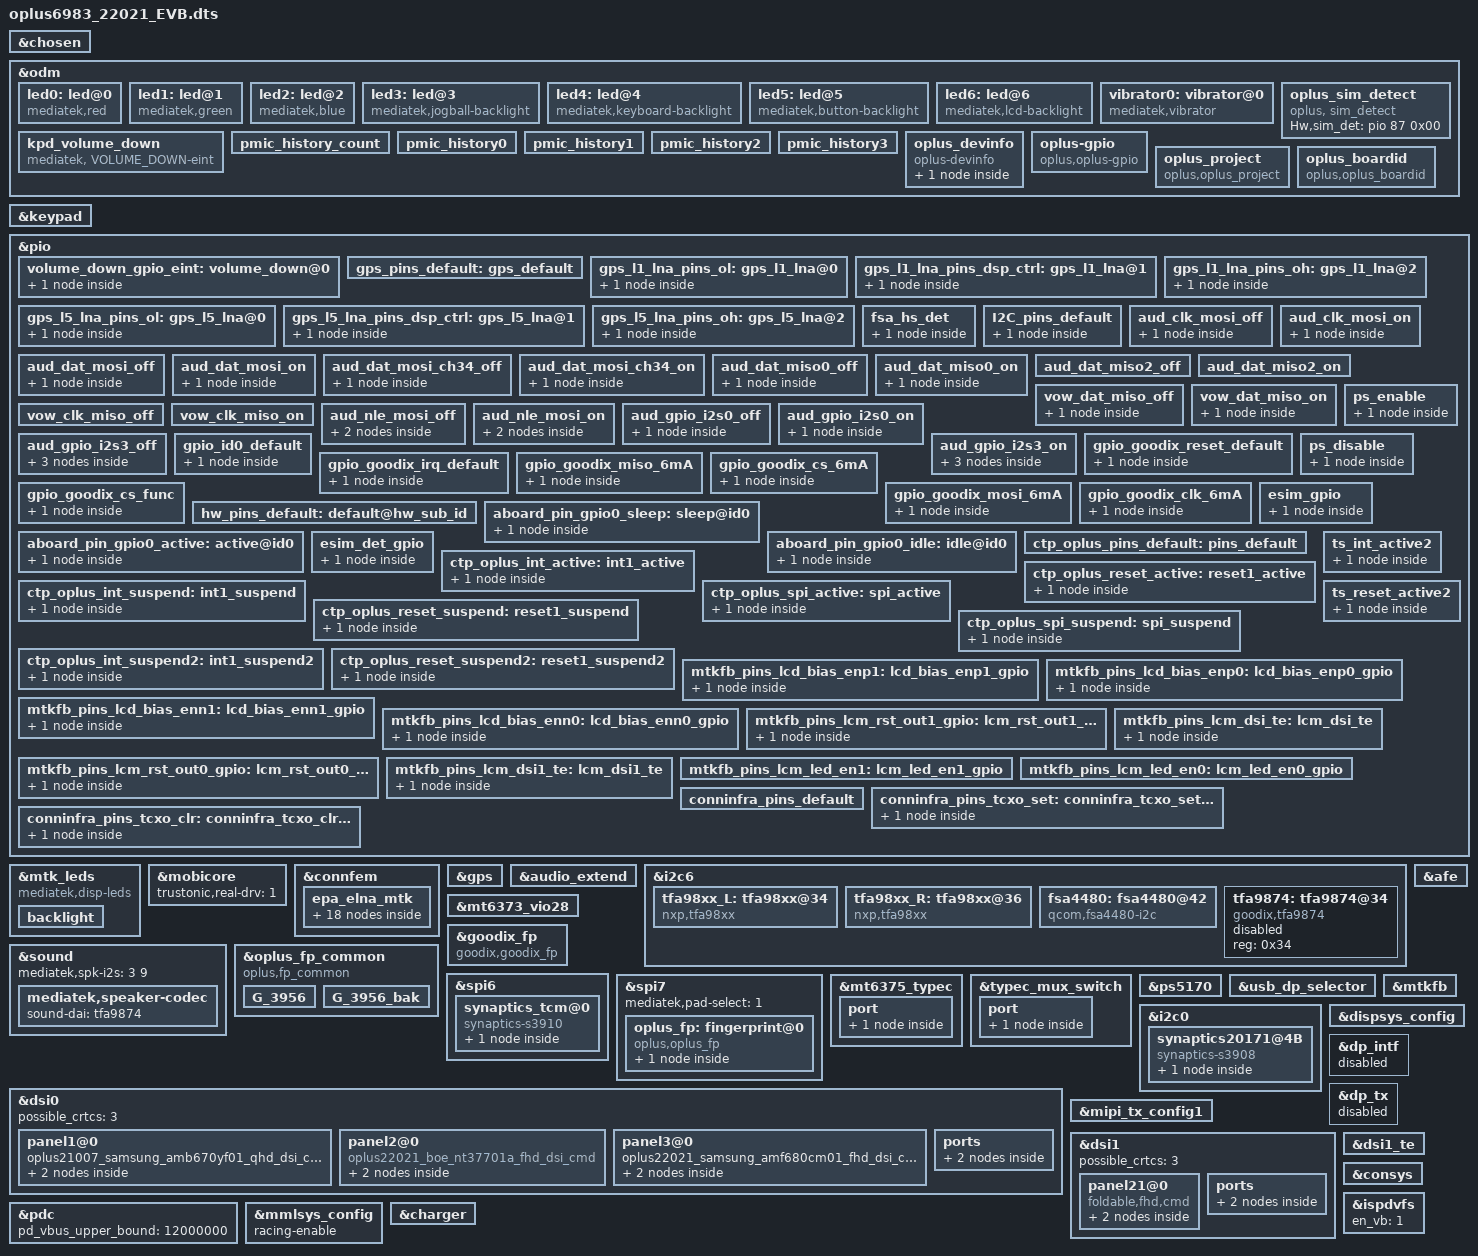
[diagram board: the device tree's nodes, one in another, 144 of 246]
// SPDX-License-Identifier: (GPL-2.0 OR MIT)
/*
 * Copyright (C) 2020 MediaTek Inc.
 */
/dts-v1/;
/plugin/;
#include <dt-bindings/interrupt-controller/arm-gic.h>
#include <dt-bindings/interrupt-controller/irq.h>
#include <dt-bindings/pinctrl/mt6983-pinfunc.h>
#include <dt-bindings/clock/mt6983-clk.h>
#include <dt-bindings/phy/phy.h>

//#ifdef OPLUS_FEATURE_CHG_BASIC
#include "mediatek/oplus_charge_22021.dtsi"
//#endif

//#ifdef OPLUS_FEATURE_SENSOR
#include "mediatek/oplus_sensor_22021.dtsi"
//#endif

//#ifdef OPLUS_FEATURE_NFC_BRINGUP
#include "mediatek/nfc/mt6983_dragonfly_22021_sn110.dtsi"
//#endif OPLUS_FEATURE_NFC_BRINGUP

#include "mediatek/fan53870-regulator_22021_EVB.dtsi"

#include "mediatek/cust_mt6983_dragonfly_22021_msdc.dtsi"

&chosen {
	bootargs_ext = "console=tty0 root=/dev/ram \
	androidboot.hardware=mt6983 \
	firmware_class.path=/vendor/firmware \
	allow_mismatched_32bit_el0";
};

&odm {
	led0:led@0 {
		compatible = "mediatek,red";
		led_mode = <0>;
		data = <1>;
		pwm_config = <0 0 0 0 0>;
	};
	led1:led@1 {
		compatible = "mediatek,green";
		led_mode = <0>;
		data = <1>;
		pwm_config = <0 0 0 0 0>;
	};
	led2:led@2 {
		compatible = "mediatek,blue";
		led_mode = <0>;
		data = <1>;
		pwm_config = <0 0 0 0 0>;
	};
	led3:led@3 {
		compatible = "mediatek,jogball-backlight";
		led_mode = <0>;
		data = <1>;
		pwm_config = <0 0 0 0 0>;
	};
	led4:led@4 {
		compatible = "mediatek,keyboard-backlight";
		led_mode = <0>;
		data = <1>;
		pwm_config = <0 0 0 0 0>;
	};
	led5:led@5 {
		compatible = "mediatek,button-backlight";
		led_mode = <0>;
		data = <1>;
		pwm_config = <0 0 0 0 0>;
	};
	led6:led@6 {
		compatible = "mediatek,lcd-backlight";
		led_mode = <4>;
		data = <1>;
		pwm_config = <0 1 0 0 0>;
	};
	vibrator0:vibrator@0 {
		compatible = "mediatek,vibrator";
		vib_timer = <25>;
		vib_limit = <9>;
		vib_vol= <9>;
	};
	kpd_volume_down:kpd_volume_down {
		compatible = "mediatek, VOLUME_DOWN-eint";
		interrupt-parent = <&pio>;
		interrupts = <12 IRQ_TYPE_EDGE_FALLING 12 0>;
		debounce = <32000>;
		status = "okay";
	};
};

&keypad {
	keypad,volume-down = <&pio 12 0x00>;
	pinctrl-names = "volume_down_as_int";
	pinctrl-0 = <&volume_down_gpio_eint>;
	status = "okay";
};

&pio {
	volume_down_gpio_eint:volume_down@0{
		pins_cmd_dat {
			pinmux = <PINMUX_GPIO12__FUNC_GPIO12>;
			slew-rate = <0>;  /*direction 0:in, 1:out*/
			input-enable;
		};
	};
};

&mtk_leds {
	compatible = "mediatek,disp-leds";
	backlight {
		label = "lcd-backlight";
		led_mode = <4>;
		max-brightness = <10239>;
		max-hw-brightness = <10239>;
		led-bits = <13>;
		};
};

/*Trustonic Mobicore real driver*/
&mobicore {
	trustonic,real-drv=<1>;
};

&connfem {
#if 0 /* Enable epa_elna node to support Wifi & BT ePA/eLNA FEM on customer load */
	epa_elna {
		parts = <&wlan7207h &wlan7205c>;

		wifi {
			flags-0 {
				open-loop;
			};
		};

		bt {
			flags-0 {
				/* choose one of: epa_elna / epa / elna / bypass */
				epa_elna;
			};
		};
	};
#endif

	epa_elna_mtk {
		parts = <&nofem &nofem>,		/* [0]iPA/iLNA */
			<&wlan7207h &wlan7205c_laa>,	/* [1]ePA/eLNA - Closed-Loop, LAA 4x4 */
			<&wlan7207h &wlan7205c>,	/* [2]ePA/eLNA - Open Loop */
			<&wlan7207h &wlan7205c>,	/* [3]ePA/eLNA - Closed-Loop */
			<&wlan7207h &wlan7205c_laa>,	/* [4]ePA/eLNA - Closed-Loop, LAA 4x4 */
			<&wlan7207h &wlan7205c>,	/* [5]ePA/eLNA - Closed-Loop + BT Bypass */
			<&wlan7207h &wlan7205c>,	/* [6]ePA/eLNA - Open Loop + BT Bypass */
			<&qm42195 &qm45197_laa>,	/* [7]Qorvo eFEM - Closed-Loop, LAA 4x4 */
			<&qm42195 &qm45197>,		/* [8]Qorvo eFEM - Open Loop */
			<&qm42195 &qm45197>;		/* [9]Qorvo eFEM - Closed-Loop */

		hwid {
			gpio = <&pio 203 0x0>;
		};

		wifi {
			flags-1 {
				laa;
			};
			flags-2 {
				open-loop;
			};
			flags-4 {
				laa;
			};
			flags-6 {
				open-loop;
			};
			flags-7 {
				laa;
			};
			flags-8 {
				open-loop;
			};
		};

		bt {
			flags-1 {
				/* choose one of: epa_elna / epa / elna / bypass */
				epa_elna;
			};
			flags-2 {
				epa_elna;
			};
			flags-3 {
				epa_elna;
			};
			flags-4 {
				epa_elna;
			};
			flags-5 {
				bypass;
			};
			flags-6 {
				bypass;
			};
			flags-7 {
				epa_elna;
			};
			flags-8 {
				epa_elna;
			};
			flags-9 {
				epa_elna;
			};
		};
	};
};

/* GPS GPIO standardization start */
&pio {
	gps_pins_default: gps_default {
	};

	gps_l1_lna_pins_ol: gps_l1_lna@0 {
		pins_cmd_dat {
			pinmux = <PINMUX_GPIO16__FUNC_GPIO16>;
			output-low;
		};
	};
	gps_l1_lna_pins_dsp_ctrl: gps_l1_lna@1 {
		pins_cmd_dat {
			pinmux = <PINMUX_GPIO16__FUNC_GPS_L1_ELNA_EN>;
		};
	};
	gps_l1_lna_pins_oh: gps_l1_lna@2 {
		pins_cmd_dat {
			pinmux = <PINMUX_GPIO16__FUNC_GPIO16>;
			output-high;
		};
	};

	gps_l5_lna_pins_ol: gps_l5_lna@0 {
		pins_cmd_dat {
			pinmux = <PINMUX_GPIO17__FUNC_GPIO17>;
			output-low;
		};
	};
	gps_l5_lna_pins_dsp_ctrl: gps_l5_lna@1 {
		pins_cmd_dat {
			pinmux = <PINMUX_GPIO17__FUNC_GPS_L5_ELNA_EN>;
		};
	};
	gps_l5_lna_pins_oh: gps_l5_lna@2 {
		pins_cmd_dat {
			pinmux = <PINMUX_GPIO17__FUNC_GPIO17>;
			output-high;
		};
	};
};

&gps {
	pinctrl-names = "default",
		"gps_l1_lna_disable",
		"gps_l1_lna_dsp_ctrl",
		"gps_l1_lna_enable",
		"gps_l5_lna_disable",
		"gps_l5_lna_dsp_ctrl",
		"gps_l5_lna_enable";
	pinctrl-0 = <&gps_pins_default>;
	pinctrl-1 = <&gps_l1_lna_pins_ol>;
	pinctrl-2 = <&gps_l1_lna_pins_dsp_ctrl>;
	pinctrl-3 = <&gps_l1_lna_pins_oh>;
	pinctrl-4 = <&gps_l5_lna_pins_ol>;
	pinctrl-5 = <&gps_l5_lna_pins_dsp_ctrl>;
	pinctrl-6 = <&gps_l5_lna_pins_oh>;
	status = "okay";
};
/* GPS GPIO standardization end */

//#ifdef OPLUS_ARCH_EXTENDS
&audio_extend {
	//for nxp speaker
	oplus,speaker-vendor = "nxp";
	oplus,speaker-i2s-id = <3>;
	oplus,speaker-i2s-id-in = <0>;
	oplus,speaker-codec-name = "tfa98xx.6-0034","tfa98xx.6-0036";
	oplus,speaker-codec-dai-name = "tfa98xx-aif-6-34","tfa98xx-aif-6-36";
};

&i2c6 {
	clock-frequency = <400000>;
	pinctrl-names = "default";
	pinctrl-0 = <&I2C_pins_default>;
	status = "okay";
	tfa98xx_L: tfa98xx@34 {
		compatible = "nxp,tfa98xx";
		reg = <0x34>;
		reset-gpio = <&mt6373_pio 2 0>;
		tfa_min_range = <5000>;
		tfa_max_range = <8000>;
		tfa_channel = <0>;
		status = "okay";
	};

	tfa98xx_R: tfa98xx@36 {
		compatible = "nxp,tfa98xx";
		reg = <0x36>;
		reset-gpio = <&mt6373_pio 1 0>;
		tfa_min_range = <5000>;
		tfa_max_range = <8000>;
		tfa_channel = <1>;
		status = "okay";
	};
};

&i2c6 {
	fsa4480: fsa4480@42 {
		compatible = "qcom,fsa4480-i2c";
		reg = <0x42>;
		fsa_audio-supply = <&mt6373_vio28>;
		pinctrl-names = "default";
		pinctrl-0 = <&fsa_hs_det>;
		fsa4480,hs-det-gpio = <&pio 98 0>;
	};
};

&pio {
	fsa_hs_det: fsa_hs_det {
		pins_cmd_dat {
			pinmux = <PINMUX_GPIO98__FUNC_GPIO98>;
			slew-rate = <1>;  /*direction 0:in, 1:out*/
			output-high;
		};
	};
};

&pio {
	I2C_pins_default: I2C_pins_default {
		pins_cmd_dat {
			pinmux = <PINMUX_GPIO49__FUNC_SCP_SCL1>,
					<PINMUX_GPIO50__FUNC_SCP_SDA1>;
			/* 0x0:75k 0x1:3k 0x2:5k 0x3:1.5k */
			/* 0x4:10k 0x5:2k 0x6:4k 0x7:1k */
			bias-pull-up = <MTK_PULL_SET_RSEL_101>;
		};
	};
};
//#endif /*OPLUS_ARCH_EXTENDS*/

&i2c6 {
	tfa9874: tfa9874@34 {
		compatible = "goodix,tfa9874";
		#sound-dai-cells = <0>;
		reg = <0x34>;
		status = "disabled";
	};
};
/*
&i2c6 {
	spk1: speaker_amp@5c {
		compatible = "richtek,rt5512";
		#sound-dai-cells = <0>;
		reg = <0x5c>;
		status = "okay";
		sound-name-prefix = "Left";
	};

	spk2: speaker_amp@5d {
		compatible = "richtek,rt5512";
		#sound-dai-cells = <0>;
		reg = <0x5d>;
		status = "okay";
		sound-name-prefix = "Right";
	};
};*/

&sound {
	mediatek,spk-i2s = <3 9>;
	mediatek,speaker-codec {
		sound-dai = <&tfa9874>;
	};
};

/* AUDIO GPIO standardization start */
&afe {
	pinctrl-names = "aud_clk_mosi_off",
			"aud_clk_mosi_on",
			"aud_dat_mosi_off",
			"aud_dat_mosi_on",
			"aud_dat_mosi_ch34_off",
			"aud_dat_mosi_ch34_on",
			"aud_dat_miso0_off",
			"aud_dat_miso0_on",
			"aud_dat_miso2_off",
			"aud_dat_miso2_on",
			"vow_dat_miso_off",
			"vow_dat_miso_on",
			"vow_clk_miso_off",
			"vow_clk_miso_on",
			"aud_gpio_i2s0_off",
			"aud_gpio_i2s0_on",
			"aud_gpio_i2s3_off",
			"aud_gpio_i2s3_on";
	pinctrl-0 = <&aud_clk_mosi_off>;
	pinctrl-1 = <&aud_clk_mosi_on>;
	pinctrl-2 = <&aud_dat_mosi_off>;
	pinctrl-3 = <&aud_dat_mosi_on>;
	pinctrl-4 = <&aud_dat_mosi_ch34_off>;
	pinctrl-5 = <&aud_dat_mosi_ch34_on>;
	pinctrl-6 = <&aud_dat_miso0_off>;
	pinctrl-7 = <&aud_dat_miso0_on>;
	pinctrl-8 = <&aud_dat_miso2_off>;
	pinctrl-9 = <&aud_dat_miso2_on>;
	pinctrl-10 = <&vow_dat_miso_off>;
	pinctrl-11 = <&vow_dat_miso_on>;
	pinctrl-12 = <&vow_clk_miso_off>;
	pinctrl-13 = <&vow_clk_miso_on>;
	pinctrl-14 = <&aud_gpio_i2s0_off>;
	pinctrl-15 = <&aud_gpio_i2s0_on>;
	pinctrl-16 = <&aud_gpio_i2s3_off>;
	pinctrl-17 = <&aud_gpio_i2s3_on>;
};
&pio {
	aud_clk_mosi_off: aud_clk_mosi_off {
		pins_cmd0_dat {
			pinmux = <PINMUX_GPIO51__FUNC_GPIO51>;
			input-enable;
			bias-pull-down;
		};
	};
	aud_clk_mosi_on: aud_clk_mosi_on {
		pins_cmd0_dat {
			pinmux = <PINMUX_GPIO51__FUNC_AUD_CLK_MOSI>;
			input-schmitt-enable;
			bias-disable;
		};
	};
	aud_dat_mosi_off: aud_dat_mosi_off {
		pins_cmd1_dat {
			pinmux = <PINMUX_GPIO52__FUNC_GPIO52>;
			input-enable;
			bias-pull-down;
		};
	};
	aud_dat_mosi_on: aud_dat_mosi_on {
		pins_cmd1_dat {
			pinmux = <PINMUX_GPIO52__FUNC_AUD_DAT_MOSI0>;
			input-schmitt-enable;
			bias-disable;
		};
	};
	aud_dat_mosi_ch34_off: aud_dat_mosi_ch34_off {
		pins_cmd1_dat {
			pinmux = <PINMUX_GPIO53__FUNC_GPIO53>;
			input-enable;
			bias-pull-down;
		};
	};
	aud_dat_mosi_ch34_on: aud_dat_mosi_ch34_on {
		pins_cmd1_dat {
			pinmux = <PINMUX_GPIO53__FUNC_AUD_DAT_MOSI1>;
			input-schmitt-enable;
			bias-disable;
		};
	};
	aud_dat_miso0_off: aud_dat_miso0_off {
		pins_cmd1_dat {
			pinmux = <PINMUX_GPIO54__FUNC_GPIO54>;
			input-enable;
			bias-pull-down;
		};
	};
	aud_dat_miso0_on: aud_dat_miso0_on {
		pins_cmd1_dat {
			pinmux = <PINMUX_GPIO54__FUNC_AUD_DAT_MISO0>;
			input-schmitt-enable;
			bias-disable;
		};
	};
	aud_dat_miso2_off: aud_dat_miso2_off {
	/* NC GPIO0,GPIO1,GPIO2 */
	};
	aud_dat_miso2_on: aud_dat_miso2_on {
	/* NC GPIO0,GPIO1,GPIO2 */
	};
	vow_dat_miso_off: vow_dat_miso_off {
		pins_cmd1_dat {
			pinmux = <PINMUX_GPIO54__FUNC_GPIO54>;
			input-enable;
			bias-pull-down;
		};
	};
	vow_dat_miso_on: vow_dat_miso_on {
		pins_cmd1_dat {
			pinmux = <PINMUX_GPIO54__FUNC_VOW_DAT_MISO>;
			input-schmitt-enable;
			bias-disable;
		};
	};
	vow_clk_miso_off: vow_clk_miso_off {
	/* NC GPIO0,GPIO1,GPIO2 */
	};
	vow_clk_miso_on: vow_clk_miso_on {
	/* NC GPIO0,GPIO1,GPIO2 */
	};
	aud_nle_mosi_off: aud_nle_mosi_off {
		pins_cmd1_dat {
			pinmux = <PINMUX_GPIO49__FUNC_GPIO49>;
			input-enable;
			bias-pull-down;
		};
		pins_cmd2_dat {
			pinmux = <PINMUX_GPIO50__FUNC_GPIO50>;
			input-enable;
			bias-pull-down;
		};
	};
	aud_nle_mosi_on: aud_nle_mosi_on {
		pins_cmd1_dat {
			pinmux = <PINMUX_GPIO49__FUNC_AUD_NLE_MOSI0>;
			input-schmitt-enable;
			bias-disable;
		};
		pins_cmd2_dat {
			pinmux = <PINMUX_GPIO50__FUNC_AUD_NLE_MOSI1>;
			input-schmitt-enable;
			bias-disable;
		};
	};
	aud_gpio_i2s0_off: aud_gpio_i2s0_off {
		pins_cmd1_dat {
			pinmux = <PINMUX_GPIO28__FUNC_GPIO28>;
			input-enable;
			bias-pull-down;
		};
	};
	aud_gpio_i2s0_on: aud_gpio_i2s0_on {
		pins_cmd1_dat {
			pinmux = <PINMUX_GPIO28__FUNC_I2S0_DI>;
			input-schmitt-enable;
			bias-disable;
		};
	};
	aud_gpio_i2s3_off: aud_gpio_i2s3_off {
		pins_cmd1_dat {
			pinmux = <PINMUX_GPIO26__FUNC_GPIO26>;
			input-enable;
			bias-pull-down;
		};
		pins_cmd2_dat {
			pinmux = <PINMUX_GPIO27__FUNC_GPIO27>;
			input-enable;
			bias-pull-down;
		};
		pins_cmd3_dat {
			pinmux = <PINMUX_GPIO29__FUNC_GPIO29>;
			input-enable;
			bias-pull-down;
		};
	};
	aud_gpio_i2s3_on: aud_gpio_i2s3_on {
		pins_cmd1_dat {
			pinmux = <PINMUX_GPIO26__FUNC_I2S3_BCK>;
			input-schmitt-enable;
			bias-disable;
		};
		pins_cmd2_dat {
			pinmux = <PINMUX_GPIO27__FUNC_I2S3_LRCK>;
			input-schmitt-enable;
			bias-disable;
		};
		pins_cmd3_dat {
			pinmux = <PINMUX_GPIO29__FUNC_I2S3_DO>;
			input-schmitt-enable;
			bias-disable;
		};
	};
};
/* AUDIO GPIO standardization end */

&mt6373_vio28 {
       regulator-min-microvolt = <3000000>;
       regulator-max-microvolt = <3000000>;
};

/* ifdef OPLUS_FEATURE_FINGERPRINT */
&oplus_fp_common {
    compatible = "oplus,fp_common";
    oplus,fp_gpio_num = <1>;
    oplus,fp_gpio_0 = <&pio 146 0x0>;
    pinctrl-names = "default";
    pinctrl-0 = <&gpio_id0_default>;
    G_3956 {
        oplus,fp-id = <1>; // fp id mapping table
        vendor-chip = <27>; // please refer to the struct fp_vendor_t in oplusfp_commmon.n
        eng-menu = "-1,-1"; // represents SNR, inclination test item in engineer menu, and 0/1 means off/on
        chip-name = "G_3956";  // /proc/fp_id, will be displayed in engineer menu
    };
    G_3956_bak {
        oplus,fp-id = <0>; // fp id mapping table
        vendor-chip = <27>; // please refer to the struct fp_vendor_t in oplusfp_commmon.n
        eng-menu = "-1,-1"; // represents SNR, inclination test item in engineer menu, and 0/1 means off/on
        chip-name = "G_3956";  // /proc/fp_id, will be displayed in engineer menu
    };
};

&pio {
    gpio_id0_default: gpio_id0_default {
        pins_cmd_dat {
            pinmux = <PINMUX_GPIO146__FUNC_GPIO146>;
            slew-rate = <0>;
            bias-pull-up = <00>;
            input-enable;
        };
    };
};

&goodix_fp {
    compatible = "goodix,goodix_fp";
    goodix,gpio_irq = <&pio 9 0x00>;
    goodix,gpio_reset = <&pio 69 0x00>;
    goodix,gpio_cs = <&pio 169 0x00>;
    pinctrl-names = "default", "gf_spi_drive_6mA", "gf_cs_func";
    pinctrl-0 = <&gpio_goodix_irq_default>, <&gpio_goodix_reset_default>;
    pinctrl-1 = <&gpio_goodix_clk_6mA>, <&gpio_goodix_mosi_6mA>, <&gpio_goodix_miso_6mA>, <&gpio_goodix_cs_6mA>;
    pinctrl-2 = <&gpio_goodix_cs_func>;
    status = "okay";
};

&spi6 {
	status = "okay";
	#address-cells = <1>;
	#size-cells = <0>;

	synaptics_tcm@0{
		compatible = "synaptics-s3910";
		reg = <0x0>;
		chip-name = "S3910";
		status = "okay";
		spi-max-frequency = <5000000>;
		/* Interrupt && Irq-gpio */
		interrupt-parent = <&pio>;
		interrupts = <8 0x2008>;

		/* Power Config */
		//enable2v8_gpio  = <&pio 164 0x1>;
		vdd_2v8-supply  = <&mt6373_vtp>;
		vdd_2v8_volt = <3000000>;
		vcc_1v8-supply  = <&fan53870_ldo7b>;
		vcc_1v8_volt = <1804000>;

		/* Other HW Resource */
		irq-gpio = <&pio 8 0x2008>;
		reset-gpio = <&pio 3 0x1>;
		prrst-gpio = <&mt6373_pio 1 0>;

		pinctrl-names = "default",  "oplus_int_active",
		"oplus_reset_active", "oplus_int_suspend",
		"oplus_reset_suspend", "oplus_spi_active",
		"oplus_spi_suspend";
		pinctrl-0 = <&ctp_oplus_pins_default>;
		pinctrl-1 = <&ctp_oplus_int_active>;
		pinctrl-2 = <&ctp_oplus_reset_active>;
		pinctrl-3 = <&ctp_oplus_int_suspend>;
		pinctrl-4 = <&ctp_oplus_reset_suspend>;
		pinctrl-5 = <&ctp_oplus_spi_active>;
		pinctrl-6 = <&ctp_oplus_spi_suspend>;

		touchpanel,max-num-support = <10>;
		touchpanel,tx-rx-num = <17 40>;
		earsense,tx-rx-num = <17 18>;
		touchpanel,panel-coords = <10800 25200>;
		touchpanel,display-coords = <1080 2520>;
		touchpanel,touchmajor-limit = <128 216>;
		touchpanel,elimination-range = <20 200 200>;
		touchpanel,int-mode = <1>; /*0: interrupt and disable, 1:interrupt and not disable*/
		touchpanel,smooth-level = <0 1 2 5 8 9>;
		touchpanel,smooth-level-charging = <0 2 4 8 9 10>;
		touchpanel,sensitive-level = <0 70 55 40 25 10>;
		touchpanel,single-optimized-time = <8>;
		touchpanel,high-frame-rate-time = <60>;

		touchpanel,tp-index = <0>;
		vid_len = <2>;
		panel_type = <3 8>; /*type:3 BOE  type:8 SAMSUNG*/
		platform_support_project = <22021 22221>;
		platform_support_project_dir = <22021 22021>;
		platform_support_project_commandline = "oplus22021_boe_nt37705_fhd_cmd","oplus22021_samsung_amf680cm01_fhd_dsi_cmd";

		prevention,curved_screen_V2;
		prevention,grip_disable_level = <6>;
		prevention,updelay_time_ms = <30>;
		prevention,makeup_cnt_weight = <5 1 2 2 2>;
		prevention,large_corner_range = <960 2400>;
		prevention,large_corner_judge_condition = <850 100 800 7 7>;
		prevention,trx_reject_condition = <8 7 7>;
		prevention,trx_strict_reject_condition = <8 6 6>;
		prevention,large_judge_time_ms = <500 50 30>;
		prevention,large_exit_condition = <8 8 2>;
		prevention,single_channel_width = <160 160>;
		prevention,normal_tap_condition = <10 350>;
		prevention,long_edge_condition = <300 150 180 80>;
		prevention,long_strict_edge_condition = <120 60>;
		prevention,long_fingerhold_condition = <70 6 4 4>;
		prevention,short_edge_condition = <250 90 180 80>;
		prevention,short_strict_edge_condition = <160 60>;
		prevention,large_strict_exit_condition = <6 6>;
		prevention,top_corner_config = <250 750 100>;
		prevention,edge_swipe_config = <150 500>;

		/* SW Support Feature Control */
		regulator_count_not_support;
		black_gesture_support;
		sportify_aod_gesture_support;
		pressure_report_support;
		charger_pump_support;
		game_switch_support;
		smart_gesture_support;
		spi_port_support;
		fw_update_app_support;
		fingerprint_underscreen_support;
		exception_upload_support;
		freq_hop_simulate_support;
		report_flow_unlock_support;
		screenoff_fingerprint_info_support;
		irq_need_dev_resume_ok;
		enable_point_auto_change;
		report_rate_white_list_support;
		kernel_grip_support;
		//grip_no_driver_support;
		health_monitor_support;
		black_gesture_indep_support;
		algorithm_support;
		snr_read_support;
		/*
		 *Virtual Key Config:
		 *1:touchpanel,button-type: <virtualkey_type  supportted_button-map>
		 *virtualkey_type:
		 *Type 1: using board_properties
		 *Type 2: using same IC (button zone&& touch zone are seprate)
		 *Type 3: using diffrent IC (button zone&& touch zone are seprate)
		 *Type 4: No need of virtual key process
		 *supportted_button-map:select|menu|home|back
		 *
		 *2:touchpanel,button-map
		 *type (X1,Y1)(X2,Y2)(X3,Y3)(Width_X,Hight_Y)--Only when button-type is 0
		 */
		touchpanel,button-type = <4>;
		touchpanel.button-TRx = <0 0>;

		S3910 {
			switch_report_rate;
			report_rate_default = <60>;
			report_rate_game_value = <0x03>;
			fps_report_rate = <60 2 90 3 120 3>;//1:360Hz 2:125Hz 3:240Hz
			fwupdate_bootloader = <1>;
			default_gesture_mask = <8191>;
			normal_config_version = <2>;
		};
	};

};

&spi7 {
    #address-cells = <1>;
    #size-cells = <0>;
    mediatek,pad-select = <1>;
    status = "okay";
    oplus_fp: fingerprint@0 {
        compatible = "oplus,oplus_fp";
        reg = <0>;
        spi-max-frequency = <8000000>;
        spi-id = <7>;
        spi-irq = <9>;
        spi-reg = <11017000>;
        dvdd-supply = <&mt6373_vfp>;
        dvdd-config = <3000000 3000000 150000>;
        power-num = <1>;
        status = "okay";
        power_source_1 {
            power-mode = <1>;
            power-name = "dvdd";
            power-config = "dvdd-config";
            delay-time = <0>;
        };
    };
};
// 1 = ldo power, refer to oplus_fp_common.h
&pio {
    gpio_goodix_reset_default:gpio_goodix_reset_default{
        pins_cmd_dat{
            pinmux = <PINMUX_GPIO69__FUNC_GPIO69>;
            slew-rate = <1>;
            output-low;
        };
    };

    gpio_goodix_irq_default:gpio_goodix_irq_default{
        pins_cmd_dat{
            pinmux = <PINMUX_GPIO9__FUNC_GPIO9>;
            slew-rate = <0>;
            bias-pull-down;
        };
    };

    gpio_goodix_miso_6mA:gpio_goodix_miso_6mA{
        pins_cmd_dat{
            pinmux = <PINMUX_GPIO168__FUNC_SPI7_B_MI>;
            drive-strength = <2>;
        };
    };

    gpio_goodix_cs_6mA:gpio_goodix_cs_6mA{
        pins_cmd_dat{
            pinmux = <PINMUX_GPIO169__FUNC_SPI7_B_CSB>;
            drive-strength = <2>;
        };
    };

    gpio_goodix_cs_func:gpio_goodix_cs_func{
        pins_cmd_dat{
            pinmux = <PINMUX_GPIO169__FUNC_SPI7_B_CSB>;
            drive-strength = <2>;
        };
    };

    gpio_goodix_mosi_6mA:gpio_goodix_mosi_6mA{
        pins_cmd_dat{
            pinmux = <PINMUX_GPIO170__FUNC_SPI7_B_MO>;
            drive-strength = <2>;
        };
    };

    gpio_goodix_clk_6mA:gpio_goodix_clk_6mA{
        pins_cmd_dat{
            pinmux = <PINMUX_GPIO171__FUNC_SPI7_B_CLK>;
            drive-strength = <2>;
        };
    };
};
//#endif /*OPLUS_FEATURE_FINGERPRINT*/

&odm {
//#ifdef OPLUS_FEATURE_TP_BASIC
/* Add for sim detect */
    oplus_sim_detect {
        compatible = "oplus, sim_detect";
        Hw,sim_det = <&pio 87 0x00>;
    };
//#endif /* OPLUS_FEATURE_TP_BASIC */

    pmic_history_count:pmic_history_count {
    };
    pmic_history0:pmic_history0 {
    };
    pmic_history1:pmic_history1 {
    };
    pmic_history2:pmic_history2 {
    };
    pmic_history3:pmic_history3 {
    };
};

&odm {
//#ifdef OPLUS_FEATURE_TP_BASIC
        oplus_devinfo:oplus_devinfo {
                compatible = "oplus-devinfo";
                pinctrl-names = "default", "aboard_gpio0_sleep", "aboard_gpio0_active", "aboard_gpio0_idle";
                pinctrl-0 = <&hw_pins_default>;
                pinctrl-1 = <&aboard_pin_gpio0_sleep>;
                pinctrl-2 = <&aboard_pin_gpio0_active>;
                pinctrl-3 = <&aboard_pin_gpio0_idle>;
                main-sub {
                        use_tristate_gpio;
                        compatible = "hw-match, main-sub";
                        aboard-gpio0 = <&pio 206 0x00>;
                        aboard-patterns = <0 1>;        /*0[high-resistance] 1[pull-down] 2[pull-up]*/
                        /*main board*/
                        match-projects = <22021 22221>;
                };
        };
//#endif OPLUS_FEATURE_TP_BASIC
};

&pio {
        hw_pins_default:default@hw_sub_id {
        };

        aboard_pin_gpio0_sleep:sleep@id0 {
                pins_cmd_dat {
                        pinmux = <PINMUX_GPIO206__FUNC_GPIO206>;
                        bias-pull-down = <MTK_PUPD_SET_R1R0_10>;
                        input-enable;
                };
        };

        aboard_pin_gpio0_active:active@id0 {
                pins_cmd_dat {
                        pinmux = <PINMUX_GPIO206__FUNC_GPIO206>;
                        bias-pull-up = <MTK_PUPD_SET_R1R0_01>;
                        input-enable;
                };
        };

        aboard_pin_gpio0_idle:idle@id0 {
                pins_cmd_dat {
                        pinmux = <PINMUX_GPIO206__FUNC_GPIO206>;
                        bias-pull-up = <MTK_PUPD_SET_R1R0_00>;
                        input-enable;
                };
        };
};
//#endif OPLUS_FEATURE_TP_BASIC

/* usb typec mux start */
&pio {

	ps_enable: ps_enable {
		pins_cmd_dat {
			//pinmux = <PINMUX_GPIO204__FUNC_GPIO204>;
			//output-high;
		};
	};

	ps_disable: ps_disable {
		pins_cmd_dat {
			//pinmux = <PINMUX_GPIO204__FUNC_GPIO204>;
			//output-low;
		};
	};

};

&mt6375_typec {
	port {
		tcpc_typec_usb: endpoint@0 {
			remote-endpoint = <&ssusb_mux>;
		};
	};
};

&typec_mux_switch {
	orientation-switch;
	mode-switch;
	accessory;
	port {
		ssusb_mux: endpoint@0 {
			remote-endpoint = <&tcpc_typec_usb>;
		};
	};
};

&ps5170 {
	pinctrl-names = "enable", "disable";
	pinctrl-0 = <&ps_enable>;
	pinctrl-1 = <&ps_disable>;
	status = "okay";
};

&usb_dp_selector {
	status = "okay";
};
/* usb typec mux end */

//#ifdef OPLUS_FEATRUE_ESIM
&odm {
    oplus-gpio {
        compatible = "oplus,oplus-gpio";
        pinctrl-names = "default";
        pinctrl-0 = <&esim_gpio &esim_det_gpio>;
        oplus,oplus-gpio-esim = <&pio 145 0>;
        oplus,oplus-esim-det = <&pio 163 0>;
    };
};

&pio {
    esim_gpio: esim_gpio {
        pins_cmd_dat {
            pinmux = <PINMUX_GPIO145__FUNC_GPIO145>;
            slew-rate = <1>;
            bias-disable; /* NO pull */
            drive-strength = <2>; /* 2 MA */
            output-high;
        };
    };

    esim_det_gpio: esim_det_gpio {
        pins_cmd_dat {
            pinmux = <PINMUX_GPIO163__FUNC_GPIO163>;
            slew-rate = <1>;
            bias-disable; /* NO pull */
            drive-strength = <2>; /* 2 MA */
            output-high;
        };
    };
};
//#endif /* OPLUS_FEATRUE_ESIM */

&i2c0 {
	status = "okay";
	synaptics20171@4B {
        status = "okay";
		compatible = "synaptics-s3908";
		reg = <0x4B>;
		chip-name = "S3908";

		/* Interrupt && Irq-gpio */
		interrupt-parent = <&pio>;
		interrupts = <157 0x2008>;

		/* Power Config */
		vdd_2v8-supply  = <&mt6373_vmc>;
		vdd_2v8_volt = <3000000>;
		vcc_1v8-supply  = <&fan53870_ldo4b>;
		vcc_1v8_volt = <1804000>;
		/* Other HW Resource */

		irq-gpio = <&pio 157 0x2008>;
		reset-gpio = <&pio 159 0x1>;
		pinctrl-names = "default";
		pinctrl-0 = <&ts_int_active2 &ts_reset_active2>;

		touchpanel,max-num-support = <10>;
		touchpanel,tx-rx-num = <9 17>;
		touchpanel,panel-coords = <382 720>;
		touchpanel,display-coords = <382 720>;
		touchpanel,touchmajor-limit = <0 54>;
		touchpanel,elimination-range = <20 200 200>;
		touchpanel,int-mode = <1>; /*0: interrupt and disable, 1:interrupt and not disable*/
		touchpanel,smooth-level = <0 1 2 3 8 10>;
		touchpanel,sensitive-level = <0 88 70 64 45 10>;

		touchpanel,tp-index = <1>;
		vid_len = <2>;
		panel_type = <3>; /*type:3 BOE*/

		platform_support_project = <22021 22221>;
		platform_support_project_dir = <22021 22021>;
		platform_support_project_commandline = "default_commandline","default_commandline";

		prevention,curved_screen_V2;
		prevention,grip_disable_level = <6>;
		prevention,updelay_time_ms = <30>;
		prevention,makeup_cnt_weight = <4 1 2 2 2>;
		prevention,large_corner_range = <80 90>;
		prevention,large_corner_judge_condition = <500 100 100 6 6>;
		prevention,trx_reject_condition = <8 7 7>;
		prevention,trx_strict_reject_condition = <8 5 5>;
		prevention,large_judge_time_ms = <500 50 30>;
		prevention,large_exit_condition = <8 8 2>;
		prevention,single_channel_width = <32 32>;
		prevention,normal_tap_condition = <10 300>;
		prevention,long_edge_condition = <260 90 180 220>;
		prevention,long_strict_edge_condition = <160 60>;
		prevention,long_fingerhold_condition = <100 6 4 4>;
		prevention,short_edge_condition = <200 90 180 220>;
		prevention,short_strict_edge_condition = <160 60>;
		prevention,large_strict_exit_condition = <4 4>;
		prevention,top_corner_config = <0 0 0>;
		prevention,edge_swipe_config = <30 100>;

		/* SW Support Feature Control */
		health_monitor_support;
		black_gesture_support;
		black_gesture_indep_support;
		charger_pump_support;
		lcd_tp_refresh_support;
		enable_point_auto_change;
		fw_update_app_support;
		smart_gesture_support;
		game_switch_support;
		report_flow_unlock_support;
		kernel_grip_support;
		freq_hop_simulate_support;
 		pressure_report_support;
		exception_upload_support;
		touchpanel,single-optimized-time = <8>;
 		touchpanel,high-frame-rate-time = <60>;
		regulator_count_not_support;
		/*
		 *Virtual Key Config:
		 *1:touchpanel,button-type: <virtualkey_type  supportted_button-map>
		 *virtualkey_type:
		 *Type 1: using board_properties
		 *Type 2: using same IC (button zone&& touch zone are seprate)
		 *Type 3: using diffrent IC (button zone&& touch zone are seprate)
		 *Type 4: No need of virtual key process
		 *supportted_button-map:select|menu|home|back
		 *
		 *2:touchpanel,button-map
		 *type (X1,Y1)(X2,Y2)(X3,Y3)(Width_X,Hight_Y)--Only when button-type is 0
		 */
		touchpanel,button-type = <4>;
		touchpanel.button-TRx = <0 0>;

		S3908 {
			report_rate_default = <90>;
			report_rate_game_value = <2>;
		};
	};
};

&pio {
	ctp_oplus_pins_default: pins_default {
	};
	ctp_oplus_int_active: int1_active {
		pins_cmd_dat {
			pinmux = <PINMUX_GPIO8__FUNC_GPIO8>;
			bias-disable;
			input-enable;
		};
	};
	ctp_oplus_reset_active: reset1_active {
		pins_cmd_dat {
			pinmux = <PINMUX_GPIO3__FUNC_GPIO3>;
			output-high;
		};
	};
	ctp_oplus_int_suspend: int1_suspend {
		pins_cmd_dat {
			pinmux = <PINMUX_GPIO8__FUNC_GPIO8>;
			output-low;
		};
	};
	ctp_oplus_reset_suspend: reset1_suspend {
		pins_cmd_dat {
			pinmux = <PINMUX_GPIO3__FUNC_GPIO3>;
			output-low;
		};
	};
	ctp_oplus_spi_active: spi_active {
		pins_cmd_dat {
			pinmux = <PINMUX_GPIO164__FUNC_SPI6_B_MI>,
				<PINMUX_GPIO165__FUNC_SPI6_B_CSB>,
				<PINMUX_GPIO166__FUNC_SPI6_B_MO>,
				<PINMUX_GPIO167__FUNC_SPI6_B_CLK>;
			bias-disable;
			drive-strength = <4>;
		};
	};
	ctp_oplus_spi_suspend: spi_suspend {
		pins_cmd_dat {
			pinmux = <PINMUX_GPIO164__FUNC_SPI6_B_MI>,
				<PINMUX_GPIO165__FUNC_SPI6_B_CSB>,
				<PINMUX_GPIO166__FUNC_SPI6_B_MO>,
				<PINMUX_GPIO167__FUNC_SPI6_B_CLK>;
			bias-disable;
			output-low;
			drive-strength = <4>;
		};
	};

	ts_int_active2: ts_int_active2 {
		pins_cmd_dat {
			pinmux = <PINMUX_GPIO157__FUNC_GPIO157>;
			bias-disable;
		};
	};
	ts_reset_active2: ts_reset_active2 {
		pins_cmd_dat {
			pinmux = <PINMUX_GPIO159__FUNC_GPIO159>;
			output-high;
		};
	};
	ctp_oplus_int_suspend2: int1_suspend2 {
		pins_cmd_dat {
			pinmux = <PINMUX_GPIO157__FUNC_GPIO157>;
			output-low;
		};
	};
	ctp_oplus_reset_suspend2: reset1_suspend2 {
		pins_cmd_dat {
			pinmux = <PINMUX_GPIO159__FUNC_GPIO159>;
			output-low;
		};
	};

	mtkfb_pins_lcd_bias_enp1: lcd_bias_enp1_gpio {
		pins_cmd_dat {
			pinmux = <PINMUX_GPIO84__FUNC_GPIO84>;
			slew-rate = <1>;
			output-high;
		};
	};
	mtkfb_pins_lcd_bias_enp0: lcd_bias_enp0_gpio {
		pins_cmd_dat {
			pinmux = <PINMUX_GPIO84__FUNC_GPIO84>;
			slew-rate = <1>;
			output-low;
		};
	};

	mtkfb_pins_lcd_bias_enn1: lcd_bias_enn1_gpio {
		pins_cmd_dat {
			pinmux = <PINMUX_GPIO84__FUNC_GPIO84>;
			slew-rate = <1>;
			output-high;
		};
	};

	mtkfb_pins_lcd_bias_enn0: lcd_bias_enn0_gpio {
		pins_cmd_dat {
			pinmux = <PINMUX_GPIO84__FUNC_GPIO84>;
			slew-rate = <1>;
			output-low;
		};
	};
	mtkfb_pins_lcm_rst_out1_gpio: lcm_rst_out1_gpio {
		pins_cmd_dat {
			pinmux = <PINMUX_GPIO86__FUNC_GPIO86>;
			slew-rate = <1>;
			output-high;
		};
	};
	mtkfb_pins_lcm_rst_out0_gpio: lcm_rst_out0_gpio {
		pins_cmd_dat {
			pinmux = <PINMUX_GPIO86__FUNC_GPIO86>;
			slew-rate = <1>;
			output-low;
		};
	};
	mtkfb_pins_lcm_dsi_te: lcm_dsi_te {
		pins_cmd_dat {
			pinmux = <PINMUX_GPIO85__FUNC_DSI_TE>;
		};
	};

	mtkfb_pins_lcm_dsi1_te: lcm_dsi1_te {
		pins_cmd_dat {
			pinmux = <PINMUX_GPIO24__FUNC_DSI1_TE>;
		};
	};

	mtkfb_pins_lcm_led_en1: lcm_led_en1_gpio {
	};

	mtkfb_pins_lcm_led_en0: lcm_led_en0_gpio {
	};
};

&mtkfb {
	pinctrl-names = "lcd_bias_enp1_gpio", "lcd_bias_enp0_gpio",
		"lcd_bias_enn1_gpio", "lcd_bias_enn0_gpio",
		"lcm_rst_out1_gpio", "lcm_rst_out0_gpio",
		"mode_te_te", "lcm_led_en1_gpio", "lcm_led_en0_gpio",
		"mode_te_te1";
	pinctrl-0 = <&mtkfb_pins_lcd_bias_enp1>;
	pinctrl-1 = <&mtkfb_pins_lcd_bias_enp0>;
	pinctrl-2 = <&mtkfb_pins_lcd_bias_enn1>;
	pinctrl-3 = <&mtkfb_pins_lcd_bias_enn0>;
	pinctrl-4 = <&mtkfb_pins_lcm_rst_out1_gpio>;
	pinctrl-5 = <&mtkfb_pins_lcm_rst_out0_gpio>;
	pinctrl-6 = <&mtkfb_pins_lcm_dsi_te>;
	pinctrl-7 = <&mtkfb_pins_lcm_led_en1>;
	pinctrl-8 = <&mtkfb_pins_lcm_led_en0>;
	pinctrl-9 = <&mtkfb_pins_lcm_dsi1_te>;

	status = "okay";
};
&dispsys_config {
	pinctrl-names =
		"lcm_rst_out1_gpio", "lcm_rst_out0_gpio",
		"mode_te_te", "mode_te_te1";
	pinctrl-0 = <&mtkfb_pins_lcm_rst_out1_gpio>;
	pinctrl-1 = <&mtkfb_pins_lcm_rst_out0_gpio>;
	pinctrl-2 = <&mtkfb_pins_lcm_dsi_te>;
	pinctrl-3 = <&mtkfb_pins_lcm_dsi1_te>;
	enable_ext_alter_path;
	enable_output_int_switch;
	status = "okay";
	helper-value = <0>, /*MTK_DRM_OPT_STAGE*/
		<1>, /*MTK_DRM_OPT_USE_CMDQ*/
		<1>, /*MTK_DRM_OPT_USE_M4U*/
		<1>, /*MTK_DRM_OPT_MMQOS_SUPPORT*/
		<1>, /*MTK_DRM_OPT_MMDVFS_SUPPORT*/
		<0>, /*MTK_DRM_OPT_SODI_SUPPORT*/
		<1>, /*MTK_DRM_OPT_IDLE_MGR*/
		<0>, /*MTK_DRM_OPT_IDLEMGR_SWTCH_DECOUPLE*/
		<1>, /*MTK_DRM_OPT_IDLEMGR_BY_REPAINT*/
		<0>, /*MTK_DRM_OPT_IDLEMGR_ENTER_ULPS*/
		<0>, /*MTK_DRM_OPT_IDLEMGR_KEEP_LP11*/
		<0>, /*MTK_DRM_OPT_DYNAMIC_RDMA_GOLDEN_SETTING*/
		<1>, /*MTK_DRM_OPT_IDLEMGR_DISABLE_ROUTINE_IRQ*/
		<0>, /*MTK_DRM_OPT_MET_LOG*/
		<1>, /*MTK_DRM_OPT_USE_PQ*/
		<0>, /*MTK_DRM_OPT_ESD_CHECK_RECOVERY*/
		<1>, /*MTK_DRM_OPT_ESD_CHECK_SWITCH*/
		<1>, /*MTK_DRM_OPT_PRESENT_FENCE*/
		<0>, /*MTK_DRM_OPT_RDMA_UNDERFLOW_AEE*/
		<0>, /*MTK_DRM_OPT_DSI_UNDERRUN_AEE*/
		<1>, /*MTK_DRM_OPT_HRT*/
		<1>, /*MTK_DRM_OPT_HRT_MODE*/
		<0>, /*MTK_DRM_OPT_DELAYED_TRIGGER*/
		<1>, /*MTK_DRM_OPT_OVL_EXT_LAYER*/
		<0>, /*MTK_DRM_OPT_AOD*/
		<0>, /*MTK_DRM_OPT_RPO*/
		<0>, /*MTK_DRM_OPT_DUAL_PIPE*/
		<0>, /*MTK_DRM_OPT_DC_BY_HRT*/
		<1>, /*MTK_DRM_OPT_OVL_WCG*/
		<0>, /*MTK_DRM_OPT_OVL_SBCH*/
		<1>, /*MTK_DRM_OPT_COMMIT_NO_WAIT_VBLANK*/
		<0>, /*MTK_DRM_OPT_MET*/
		<0>, /*MTK_DRM_OPT_REG_PARSER_RAW_DUMP*/
		<0>, /*MTK_DRM_OPT_VP_PQ*/
		<0>, /*MTK_DRM_OPT_GAME_PQ*/
		<0>, /*MTK_DRM_OPT_MMPATH*/
		<0>, /*MTK_DRM_OPT_HBM*/
		<0>, /*MTK_DRM_OPT_VDS_PATH_SWITCH*/
		<0>, /*MTK_DRM_OPT_LAYER_REC*/
		<1>, /*MTK_DRM_OPT_CLEAR_LAYER*/
		<1>, /*MTK_DRM_OPT_LFR*/
		<0>, /*MTK_DRM_OPT_SF_PF*/
		<1>, /*MTK_DRM_OPT_DYN_MIPI_CHANGE*/
		<1>, /*MTK_DRM_OPT_PRIM_DUAL_PIPE*/
		<1>, /*MTK_DRM_OPT_MSYNC2_0*/
		<1>, /*MTK_DRM_OPT_MML_PRIMARY*/
		<0>, /*MTK_DRM_OPT_MML_SUPPORT_CMD_MODE*/
		<1>, /*MTK_DRM_OPT_MML_PQ*/
		<1>, /*MTK_DRM_OPT_DUAL_TE*/
		<1>, /*MTK_DRM_OPT_RES_SWITCH*/
		<1>, /*MTK_DRM_OPT_VIRTUAL_DISP*/
		<0>, /*MTK_DRM_OPT_PRE_TE*/
		<1>, /*MTK_DRM_OPT_OVL_BW_MONITOR*/
		<1>; /*MTK_DRM_OPT_GPU_CACHE*/
};

&dsi0 {
	status = "okay";
	#address-cells = <1>;
	#size-cells = <0>;
	possible_crtcs = <3>;
	panel1@0 {
		compatible = "oplus21007_samsung_amb670yf01_qhd_dsi_cmd";
		reg = <0>;
		vddr1p5-enable-gpios = <&pio 148 0>;
		reset-gpios = <&pio 86 0>;
		//te_switch-gpios = <&pio 24 0>;
		te_out-gpios = <&pio 36 0>;
		aod_en-gpios = <&mt6373_pio 3 0>;
		1p8-supply = <&mt6363_vufs18>;
		3p0-supply = <&mt6373_vmch>;
		pinctrl-names = "default";
		port {
			panel_in1: endpoint {
				remote-endpoint = <&dsi_out>;
			};
		};
	};
	panel2@0 {
		compatible = "oplus22021_boe_nt37701a_fhd_dsi_cmd";
		reg = <1>;
		vddr1p5-enable-gpios = <&pio 148 0>;
		reset-gpios = <&pio 86 0>;
		//te_switch-gpios = <&pio 24 0>;
		te_out-gpios = <&pio 36 0>;
		aod_en-gpios = <&mt6373_pio 3 0>;
		1p8-supply = <&mt6363_vufs18>;
		3p0-supply = <&mt6373_vmch>;
		pinctrl-names = "default";
		port {
			panel_in2: endpoint {
				remote-endpoint = <&dsi_out>;
			};
		};
	};
	panel3@0 {
		compatible = "oplus22021_samsung_amf680cm01_fhd_dsi_cmd";
		reg = <2>;
		vddr1p5-enable-gpios = <&pio 148 0>;
		reset-gpios = <&pio 86 0>;
		sm3011_reset-gpio = <&pio 195 0>;
		//te_switch-gpios = <&pio 24 0>;
		te_out-gpios = <&pio 36 0>;
		aod_en-gpios = <&mt6373_pio 3 0>;
		1p8-supply = <&mt6363_vufs18>;
		3p0-supply = <&mt6373_vmch>;
		pinctrl-names = "default";
		port {
			panel_in3: endpoint {
				remote-endpoint = <&dsi_out>;
			};
		};
	};
	ports {
		port {
			dsi_out: endpoint {
				remote-endpoint = <&panel_in1>;
			};
		};
	};
};

&dp_intf {
	status = "disabled";
};

&dp_tx {
	status = "disabled";
};

&mipi_tx_config1 {
	status = "okay";
};

&dsi1 {
	status = "okay";
	#address-cells = <1>;
	#size-cells = <0>;
	possible_crtcs = <3>;
	panel21@0 {
		compatible = "foldable,fhd,cmd";
		reg = <0>;
		pm-enable-gpios = <&pio 68 0>;
		reset-gpios = <&pio 62 0>;
		te_in-gpios = <&pio 24 0>;
		avdden-gpios = <&pio 156 0>;
		vddio_1v8-supply  = <&fan53870_ldo3b>;
		gate-ic = <4831>;
		pinctrl-names = "default";
		port {
			panel21_in: endpoint {
				remote-endpoint = <&dsi1_out>;
			};
		};
	};
	ports {
		port {
			dsi1_out: endpoint {
				remote-endpoint = <&panel21_in>;
			};
		};
	};
};

&dsi1_te {
	interrupt-parent = <&pio>;
	interrupts = <24 1 24 1>;
	status = "okay";
};

&odm {
/*OPLUS_BUG_STABILITY oplus project start */
	oplus_project:oplus_project {
		compatible = "oplus,oplus_project";
	};
/*endif*/
	oplus_boardid:oplus_boardid {
		compatible = "oplus,oplus_boardid";
		oplus_boardid,dtsino="22021";//only one u32
		oplus_boardid,pcbmask="0x2";//all mask 0xffff
	};
};

/* CONNSYS TCXO GPIO start */
&consys {
	tcxo_support = "false";
	pinctrl-names = "default", "conninfra_tcxo_set", "conninfra_tcxo_clr";
	pinctrl-0 = <&conninfra_pins_default>;
	pinctrl-1 = <&conninfra_pins_tcxo_set>;
	pinctrl-2 = <&conninfra_pins_tcxo_clr>;
	status = "okay";
};

&pio {
	conninfra_pins_default: conninfra_pins_default {
	};
	conninfra_pins_tcxo_set: conninfra_tcxo_set@gpio {
		pins_cmd_dat {
			pinmux = <PINMUX_GPIO159__FUNC_CONN_TCXOENA_REQ>;
		};
	};
	conninfra_pins_tcxo_clr: conninfra_tcxo_clr@gpio {
		pins_cmd_dat {
			pinmux = <PINMUX_GPIO159__FUNC_GPIO159>;
		};
	};
};
/* CONNSYS TCXO GPIO end */

&pdc {
	pd_vbus_upper_bound = <12000000>;
};

&mmlsys_config {
	racing-enable;
};

&ispdvfs {
	en_vb = <1>;
};

&charger {
	qcom,vooc_project = <0>;
	qcom,voocphy_support = <0>;
};

#include <oplus6983_22021/cust.dtsi>
//#include "mediatek/cust_mt6983_camera_v4l2.dtsi"
#include "mediatek/cust_mt6983_qingting_camera_v4l2_EVB.dtsi"
#include "mediatek/cust_mt6983_dragonfly_cam_thermal.dtsi"
